VERSION ""

NS_ :

BS_:

BU_:

BO_ 1298 Aero_Static_Pressure_Array_3_3: 4 Vector__XXX
 SG_ P_Scanner_3_Temperature : 23|16@0- (0.1,0) [-327.68|327.67] "C" Vector__XXX
 SG_ Aero_Static_3_P_REF : 7|16@0- (0.1,0) [-327.68|327.67] "mbar" Vector__XXX

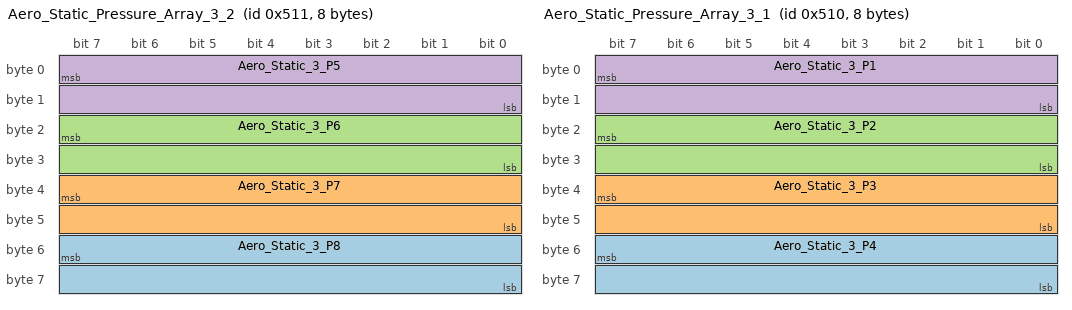
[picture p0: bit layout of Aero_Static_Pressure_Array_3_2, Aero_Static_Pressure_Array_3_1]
BO_ 1297 Aero_Static_Pressure_Array_3_2: 8 Vector__XXX
 SG_ Aero_Static_3_P8 : 55|16@0- (0.01,0) [-327.68|327.67] "mbar" Vector__XXX
 SG_ Aero_Static_3_P7 : 39|16@0- (0.01,0) [-327.68|327.67] "mbar" Vector__XXX
 SG_ Aero_Static_3_P6 : 23|16@0- (0.01,0) [-327.68|327.67] "mbar" Vector__XXX
 SG_ Aero_Static_3_P5 : 7|16@0- (0.01,0) [-327.68|327.67] "mbar" Vector__XXX

BO_ 1296 Aero_Static_Pressure_Array_3_1: 8 Vector__XXX
 SG_ Aero_Static_3_P4 : 55|16@0- (0.01,0) [-327.68|327.67] "mbar" Vector__XXX
 SG_ Aero_Static_3_P3 : 39|16@0- (0.01,0) [-327.68|327.67] "mbar" Vector__XXX
 SG_ Aero_Static_3_P2 : 23|16@0- (0.01,0) [-327.68|327.67] "mbar" Vector__XXX
 SG_ Aero_Static_3_P1 : 7|16@0- (0.01,0) [-327.68|327.67] "mbar" Vector__XXX

BO_ 1295 Aero_Static_Pressure_Array_2_3: 4 Vector__XXX
 SG_ P_Scanner_2_Temperature : 23|16@0- (0.1,0) [-327.68|327.67] "C" Vector__XXX
 SG_ Aero_Static_2_P_REF : 7|16@0- (0.1,0) [-327.68|327.67] "mbar" Vector__XXX

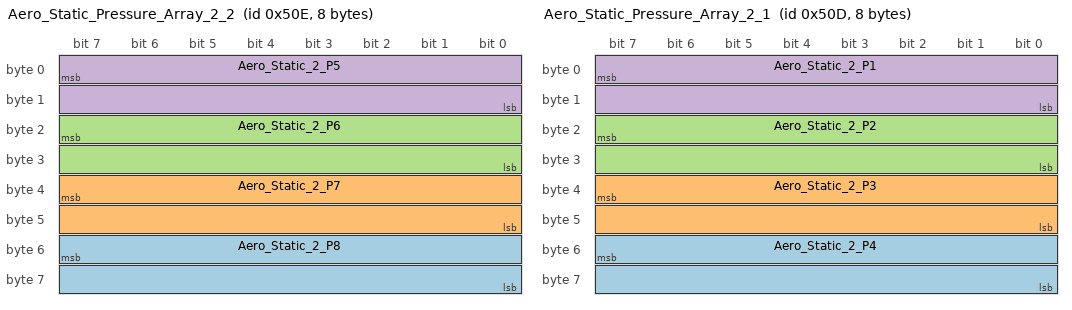
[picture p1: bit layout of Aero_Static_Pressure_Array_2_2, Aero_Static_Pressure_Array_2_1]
BO_ 1294 Aero_Static_Pressure_Array_2_2: 8 Vector__XXX
 SG_ Aero_Static_2_P8 : 55|16@0- (0.01,0) [-327.68|327.67] "mbar" Vector__XXX
 SG_ Aero_Static_2_P7 : 39|16@0- (0.01,0) [-327.68|327.67] "mbar" Vector__XXX
 SG_ Aero_Static_2_P6 : 23|16@0- (0.01,0) [-327.68|327.67] "mbar" Vector__XXX
 SG_ Aero_Static_2_P5 : 7|16@0- (0.01,0) [-327.68|327.67] "mbar" Vector__XXX

BO_ 1293 Aero_Static_Pressure_Array_2_1: 8 Vector__XXX
 SG_ Aero_Static_2_P4 : 55|16@0- (0.01,0) [-327.68|327.67] "mbar" Vector__XXX
 SG_ Aero_Static_2_P3 : 39|16@0- (0.01,0) [-327.68|327.67] "mbar" Vector__XXX
 SG_ Aero_Static_2_P2 : 23|16@0- (0.01,0) [-327.68|327.67] "mbar" Vector__XXX
 SG_ Aero_Static_2_P1 : 7|16@0- (0.01,0) [-327.68|327.67] "mbar" Vector__XXX

BO_ 1292 Aero_Static_Pressure_Array_1_3: 4 Vector__XXX
 SG_ P_Scanner_1_Temperature : 23|16@0- (0.1,0) [-327.68|327.67] "C" Vector__XXX
 SG_ Aero_Static_1_P_REF : 7|16@0- (0.1,0) [-327.68|327.67] "mbar" Vector__XXX

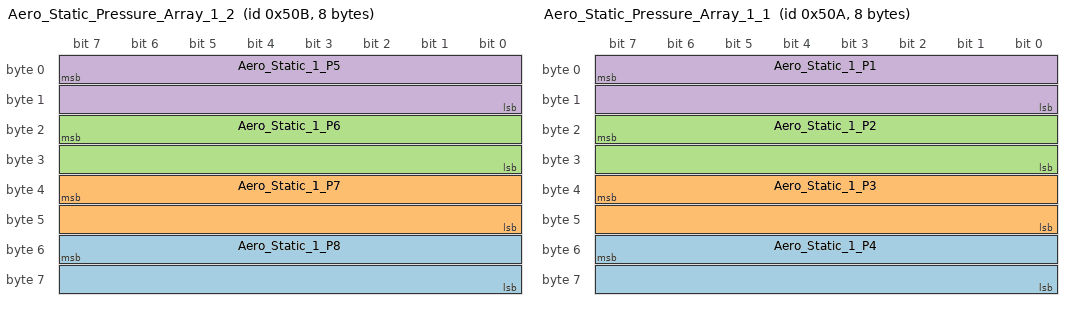
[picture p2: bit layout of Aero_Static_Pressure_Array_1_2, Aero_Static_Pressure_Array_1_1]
BO_ 1291 Aero_Static_Pressure_Array_1_2: 8 Vector__XXX
 SG_ Aero_Static_1_P8 : 55|16@0- (0.01,0) [-327.68|327.67] "mbar" Vector__XXX
 SG_ Aero_Static_1_P7 : 39|16@0- (0.01,0) [-327.68|327.67] "mbar" Vector__XXX
 SG_ Aero_Static_1_P6 : 23|16@0- (0.01,0) [-327.68|327.67] "mbar" Vector__XXX
 SG_ Aero_Static_1_P5 : 7|16@0- (0.01,0) [-327.68|327.67] "mbar" Vector__XXX

BO_ 1290 Aero_Static_Pressure_Array_1_1: 8 Vector__XXX
 SG_ Aero_Static_1_P4 : 55|16@0- (0.01,0) [-327.68|327.67] "mbar" Vector__XXX
 SG_ Aero_Static_1_P3 : 39|16@0- (0.01,0) [-327.68|327.67] "mbar" Vector__XXX
 SG_ Aero_Static_1_P2 : 23|16@0- (0.01,0) [-327.68|327.67] "mbar" Vector__XXX
 SG_ Aero_Static_1_P1 : 7|16@0- (0.01,0) [-327.68|327.67] "mbar" Vector__XXX

BA_DEF_ BO_  "GenMsgCycleTime" INT 0 0;
BA_DEF_DEF_  "GenMsgCycleTime" 0;
BA_ "GenMsgCycleTime" BO_ 1292 4;
BA_ "GenMsgCycleTime" BO_ 1291 4;
BA_ "GenMsgCycleTime" BO_ 1290 4;
